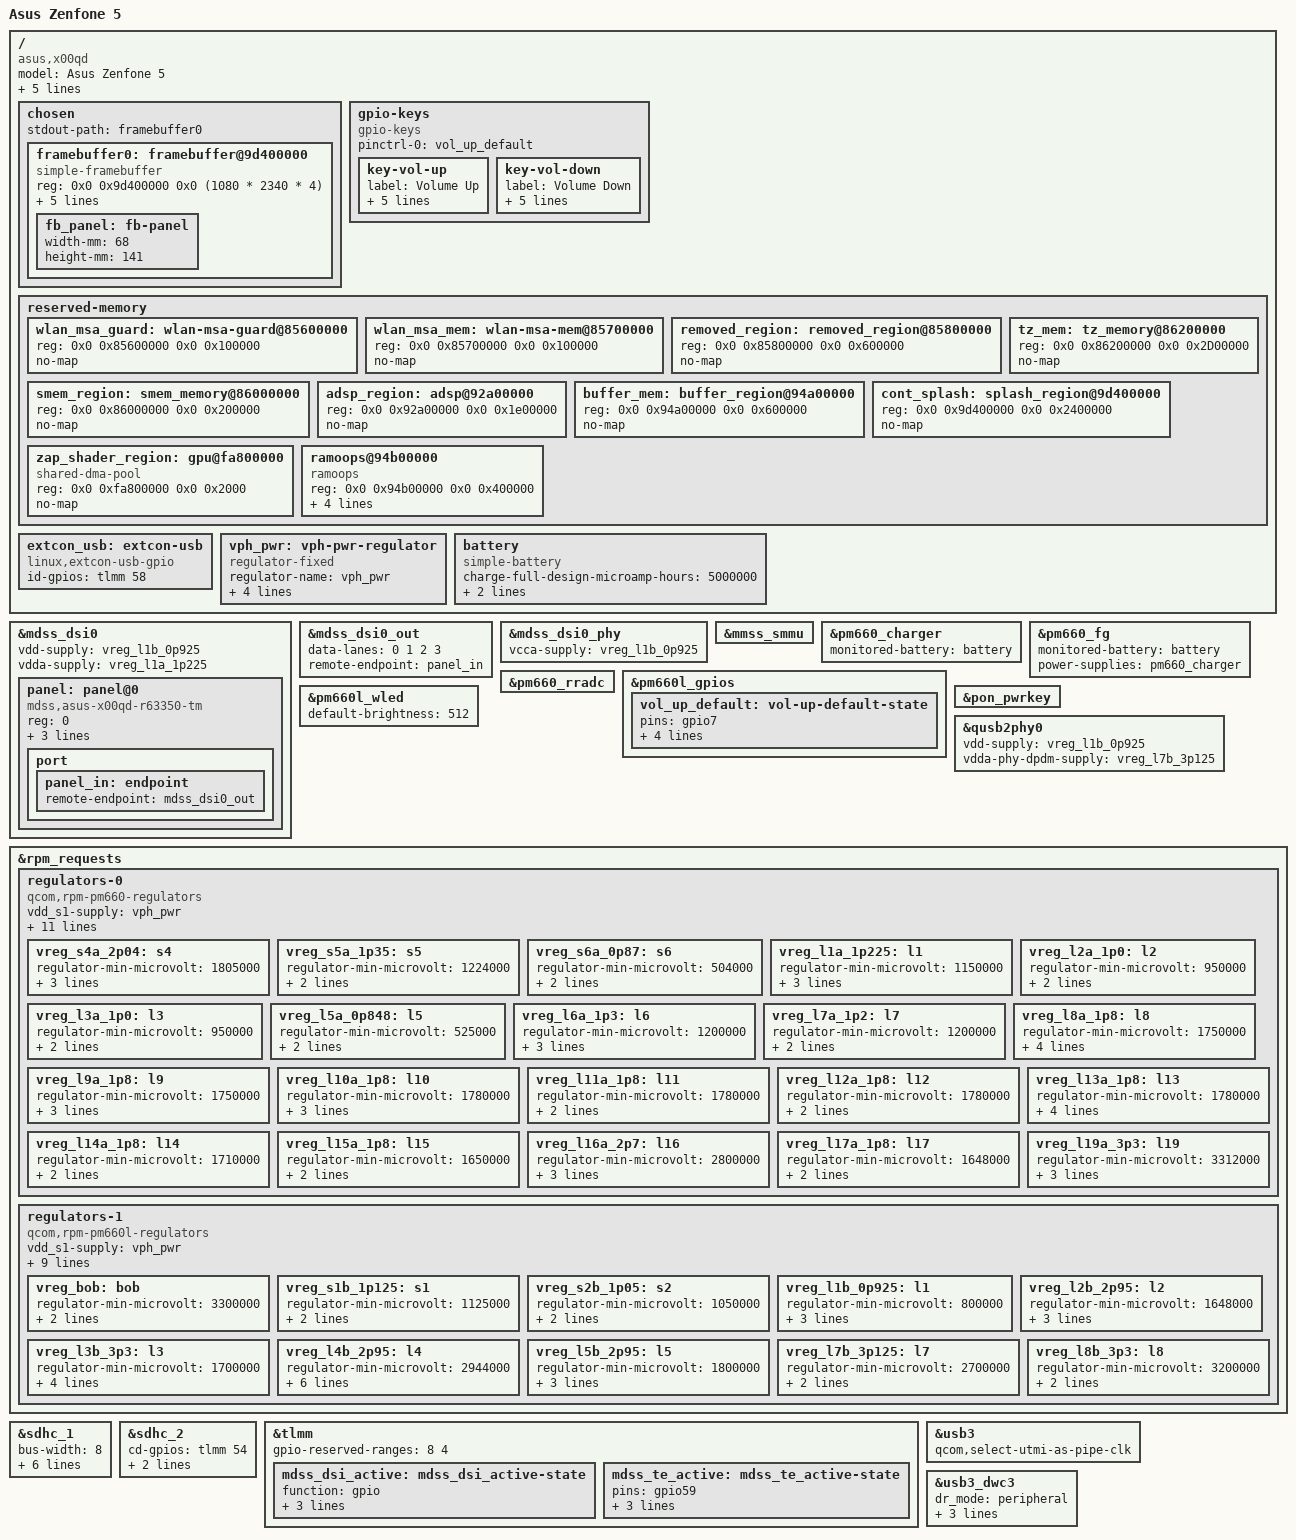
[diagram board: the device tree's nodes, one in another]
// SPDX-License-Identifier: GPL-2.0-only
/*
 * Copyright (c) 2025, Antony Kurniawan S. <postmarketos@smankusors.com>
 */

/dts-v1/;

#include "sdm636.dtsi"
#include "pm660.dtsi"
#include "pm660l.dtsi"
#include <dt-bindings/input/input.h>
#include <dt-bindings/input/gpio-keys.h>
#include <dt-bindings/pinctrl/qcom,pmic-gpio.h>

/delete-node/ &qhee_code;
/delete-node/ &smem_region;
/delete-node/ &tz_mem;
/delete-node/ &adsp_region;
/delete-node/ &buffer_mem;
/delete-node/ &zap_shader_region;

/ {
	model = "Asus Zenfone 5";
	compatible = "asus,x00qd", "qcom,sdm660";
	chassis-type = "handset";

	qcom,msm-id = <0x159 0x0>;
	qcom,board-id = <0x1000b 0>,<63 0>,<62 0>;
	qcom,pmic-id = <0x1001b 0x101011a 0x0 0x0 0x1001b 0x201011a 0x0 0x0 0x1001b 0x0102001a 0x0 0x0>;

	chosen {
		#address-cells = <2>;
		#size-cells = <2>;
		ranges;

		stdout-path = "framebuffer0";

		framebuffer0: framebuffer@9d400000 {
			compatible = "simple-framebuffer";
			reg = <0x0 0x9d400000 0x0 (1080 * 2340 * 4)>;
			status = "okay";
			width = <1080>;
			height = <2340>;
			stride = <(1080 * 4)>;
			format = "a8r8g8b8";

			/* In order to allow simpledrm framebuffer to know
			 * physical dimensions */
			panel = <&fb_panel>;

			fb_panel: fb-panel {
				width-mm = <68>;
				height-mm = <141>;
			};
		};
	};

	gpio-keys {
		status = "okay";
		compatible = "gpio-keys";

		pinctrl-0 = <&vol_up_default>;
		pinctrl-names = "default";

		key-vol-up {
			label = "Volume Up";
			gpios = <&tlmm 44 GPIO_ACTIVE_LOW>;
			linux,input-type = <1>;
			linux,code = <KEY_VOLUMEUP>;
			wakeup-source;
			debounce-interval = <15>;
		};

		key-vol-down {
			label = "Volume Down";
			gpios = <&tlmm 43 GPIO_ACTIVE_LOW>;
			linux,input-type = <1>;
			linux,code = <KEY_VOLUMEDOWN>;
			wakeup-source;
			debounce-interval = <15>;
		};
	};

	reserved-memory {
		#address-cells = <2>;
		#size-cells = <2>;
		ranges;
		wlan_msa_guard: wlan-msa-guard@85600000 {
			reg = <0x0 0x85600000 0x0 0x100000>;
			no-map;
		};

		wlan_msa_mem: wlan-msa-mem@85700000 {
			reg = <0x0 0x85700000 0x0 0x100000>;
			no-map;
		};

		/* removed_regions in downstream / qhee_code */
		removed_region: removed_region@85800000 {
			reg = <0x0 0x85800000 0x0 0x600000>;
			no-map;
		};

		smem_region: smem_memory@86000000 {
			reg = <0x0 0x86000000 0x0 0x200000>;
			no-map;
		};

		/* tz_mem */
		tz_mem: tz_memory@86200000 {
			reg = <0x0 0x86200000 0x0 0x2D00000>;
			/* 0x86200000 + 0x2D00000 = 0x88F00000 */
			no-map;
		};

		/* adsp_fw_region */
		adsp_region: adsp@92a00000 {
			reg = <0x0 0x92a00000 0x0 0x1e00000>;
			no-map;
		};

		/* cdsp_fw_region */
		buffer_mem: buffer_region@94a00000 {
			reg = <0x0 0x94a00000 0x0 0x600000>;
			no-map;
		};

		/* cont_splash_region / framebuffer */
		cont_splash: splash_region@9d400000 {
			reg = <0x0 0x9d400000 0x0 0x2400000>;
			no-map;
		};

		zap_shader_region: gpu@fa800000 {
			compatible = "shared-dma-pool";
			reg = <0x0 0xfa800000 0x0 0x2000>;
			no-map;
		};

		ramoops@94b00000 {
			compatible = "ramoops";
			reg = <0x0 0x94b00000 0x0 0x400000>;
			console-size = <0x200000>;
			record-size = <0x0>;
			ftrace-size = <0x0>;
			pmsg-size = <0x200000>;
		};
	};

	/*
	 * Until we hook up type-c detection, we
	 * have to stick with this. But it works.
	 */
	extcon_usb: extcon-usb {
		compatible = "linux,extcon-usb-gpio";
		id-gpios = <&tlmm 58 GPIO_ACTIVE_HIGH>;
	};

	vph_pwr: vph-pwr-regulator {
		compatible = "regulator-fixed";
		regulator-name = "vph_pwr";
		regulator-min-microvolt = <3700000>;
		regulator-max-microvolt = <3700000>;
		regulator-always-on;
		regulator-boot-on;
	};

	battery: battery {
			compatible = "simple-battery";

			charge-full-design-microamp-hours = <5000000>;
			voltage-min-design-microvolt = <3400000>;
			voltage-max-design-microvolt = <4350000>;
	};
};

&mdss_dsi0 {
	status = "okay";

	#address-cells = <1>;
	#size-cells = <0>;

	vdd-supply = <&vreg_l1b_0p925>;
	vdda-supply = <&vreg_l1a_1p225>;

	panel: panel@0 {
		reg = <0>;
		compatible = "mdss,asus-x00qd-r63350-tm";

		backlight = <&pm660l_wled>;

		reset-gpios = <&tlmm 53 GPIO_ACTIVE_LOW>;

		pinctrl-0 = <&mdss_dsi_active &mdss_te_active>;
		pinctrl-names = "default";

		port {
			panel_in: endpoint {
				remote-endpoint = <&mdss_dsi0_out>;
			};
		};
	};
};

&mdss_dsi0_out {
	data-lanes = <0 1 2 3>;
	remote-endpoint = <&panel_in>;
};

&mdss_dsi0_phy {
	vcca-supply = <&vreg_l1b_0p925>;

	status = "okay";
};

&mmss_smmu {
	status = "okay";
};

&pm660_charger {
	monitored-battery = <&battery>;

	status = "okay";
};

&pm660_fg {
	status = "okay";
	monitored-battery = <&battery>;
	power-supplies = <&pm660_charger>;
};

&pm660_rradc {
	status = "okay";
};

&pm660l_gpios {
	vol_up_default: vol-up-default-state {
		pins = "gpio7";
		function = PMIC_GPIO_FUNC_NORMAL;
		bias-pull-up;
		input-enable;
		qcom,drive-strength = <PMIC_GPIO_STRENGTH_NO>;
	};
};

&pm660l_wled {
	default-brightness = <512>;

	status = "okay";
};

&pon_pwrkey {
	status = "okay";
};

&qusb2phy0 {
	vdd-supply = <&vreg_l1b_0p925>;
	vdda-phy-dpdm-supply = <&vreg_l7b_3p125>;

	status = "okay";
};

&rpm_requests {
	regulators-0 {
		compatible = "qcom,rpm-pm660-regulators";

		vdd_s1-supply = <&vph_pwr>;
		vdd_s2-supply = <&vph_pwr>;
		vdd_s3-supply = <&vph_pwr>;
		vdd_s4-supply = <&vph_pwr>;
		vdd_s5-supply = <&vph_pwr>;
		vdd_s6-supply = <&vph_pwr>;

		vdd_l1_l6_l7-supply = <&vreg_s5a_1p35>;
		vdd_l2_l3-supply = <&vreg_s2b_1p05>;
		vdd_l5-supply = <&vreg_s2b_1p05>;
		vdd_l8_l9_l10_l11_l12_l13_l14-supply = <&vreg_s4a_2p04>;
		vdd_l15_l16_l17_l18_l19-supply = <&vreg_bob>;

		/*
		 * S1A (FTAPC0), S2A (FTAPC1), S3A (HFAPC1) are managed
		 * by the Core Power Reduction hardened (CPRh) and the
		 * Operating State Manager (OSM) HW automatically.
		 */

		vreg_s4a_2p04: s4 {
			regulator-min-microvolt = <1805000>;
			regulator-max-microvolt = <2040000>;
			regulator-enable-ramp-delay = <200>;
			regulator-always-on;
		};

		vreg_s5a_1p35: s5 {
			regulator-min-microvolt = <1224000>;
			regulator-max-microvolt = <1350000>;
			regulator-enable-ramp-delay = <200>;
		};

		vreg_s6a_0p87: s6 {
			regulator-min-microvolt = <504000>;
			regulator-max-microvolt = <992000>;
			regulator-enable-ramp-delay = <150>;
		};

		/* LDOs */
		vreg_l1a_1p225: l1 {
			regulator-min-microvolt = <1150000>;
			regulator-max-microvolt = <1250000>;
			regulator-enable-ramp-delay = <250>;
			regulator-allow-set-load;
		};

		vreg_l2a_1p0: l2 {
			regulator-min-microvolt = <950000>;
			regulator-max-microvolt = <1010000>;
			regulator-enable-ramp-delay = <250>;
		};

		vreg_l3a_1p0: l3 {
			regulator-min-microvolt = <950000>;
			regulator-max-microvolt = <1010000>;
			regulator-enable-ramp-delay = <250>;
		};

		vreg_l5a_0p848: l5 {
			regulator-min-microvolt = <525000>;
			regulator-max-microvolt = <950000>;
			regulator-enable-ramp-delay = <250>;
		};

		vreg_l6a_1p3: l6 {
			regulator-min-microvolt = <1200000>;
			regulator-max-microvolt = <1370000>;
			regulator-allow-set-load;
			regulator-enable-ramp-delay = <250>;
		};

		vreg_l7a_1p2: l7 {
			regulator-min-microvolt = <1200000>;
			regulator-max-microvolt = <1200000>;
			regulator-enable-ramp-delay = <250>;
		};

		vreg_l8a_1p8: l8 {
			regulator-min-microvolt = <1750000>;
			regulator-max-microvolt = <1800000>;
			regulator-enable-ramp-delay = <250>;
			regulator-system-load = <325000>;
			regulator-allow-set-load;
		};

		vreg_l9a_1p8: l9 {
			regulator-min-microvolt = <1750000>;
			regulator-max-microvolt = <1900000>;
			regulator-enable-ramp-delay = <250>;
			regulator-allow-set-load;
		};

		vreg_l10a_1p8: l10 {
			regulator-min-microvolt = <1780000>;
			regulator-max-microvolt = <1950000>;
			regulator-enable-ramp-delay = <250>;
			regulator-allow-set-load;
		};

		vreg_l11a_1p8: l11 {
			regulator-min-microvolt = <1780000>;
			regulator-max-microvolt = <1950000>;
			regulator-enable-ramp-delay = <250>;
		};

		vreg_l12a_1p8: l12 {
			regulator-min-microvolt = <1780000>;
			regulator-max-microvolt = <1950000>;
			regulator-enable-ramp-delay = <250>;
		};

		/* This gives power to the LPDDR4: never turn it off! */
		vreg_l13a_1p8: l13 {
			regulator-min-microvolt = <1780000>;
			regulator-max-microvolt = <1950000>;
			regulator-enable-ramp-delay = <250>;
			regulator-boot-on;
			regulator-always-on;
		};

		vreg_l14a_1p8: l14 {
			regulator-min-microvolt = <1710000>;
			regulator-max-microvolt = <1900000>;
			regulator-enable-ramp-delay = <250>;
		};

		vreg_l15a_1p8: l15 {
			regulator-min-microvolt = <1650000>;
			regulator-max-microvolt = <2950000>;
			regulator-enable-ramp-delay = <250>;
		};

		vreg_l16a_2p7: l16 {
			regulator-min-microvolt = <2800000>;
			regulator-max-microvolt = <2800000>;
			regulator-enable-ramp-delay = <250>;
			regulator-always-on;
		};

		vreg_l17a_1p8: l17 {
			regulator-min-microvolt = <1648000>;
			regulator-max-microvolt = <2952000>;
			regulator-enable-ramp-delay = <250>;
		};

		vreg_l19a_3p3: l19 {
			regulator-min-microvolt = <3312000>;
			regulator-max-microvolt = <3400000>;
			regulator-enable-ramp-delay = <250>;
			regulator-allow-set-load;
		};
	};

	regulators-1 {
		compatible = "qcom,rpm-pm660l-regulators";

		vdd_s1-supply = <&vph_pwr>;
		vdd_s2-supply = <&vph_pwr>;
		vdd_s3_s4-supply = <&vph_pwr>;
		vdd_s5-supply = <&vph_pwr>;
		vdd_s6-supply = <&vph_pwr>;

		vdd_l1_l9_l10-supply = <&vreg_s2b_1p05>;
		vdd_l2-supply = <&vreg_bob>;
		vdd_l3_l5_l7_l8-supply = <&vreg_bob>;
		vdd_l4_l6-supply = <&vreg_bob>;
		vdd_bob-supply = <&vph_pwr>;

		vreg_bob: bob {
			regulator-min-microvolt = <3300000>;
			regulator-max-microvolt = <3600000>;
			regulator-enable-ramp-delay = <500>;
		};

		vreg_s1b_1p125: s1 {
			regulator-min-microvolt = <1125000>;
			regulator-max-microvolt = <1125000>;
			regulator-enable-ramp-delay = <200>;
		};

		vreg_s2b_1p05: s2 {
			regulator-min-microvolt = <1050000>;
			regulator-max-microvolt = <1050000>;
			regulator-enable-ramp-delay = <200>;
		};

		/* LDOs */
		vreg_l1b_0p925: l1 {
			regulator-min-microvolt = <800000>;
			regulator-max-microvolt = <925000>;
			regulator-enable-ramp-delay = <250>;
			regulator-allow-set-load;
		};

		/* SDHCI 3.3V signal doesn't seem to be supported. */
		vreg_l2b_2p95: l2 {
			regulator-min-microvolt = <1648000>;
			regulator-max-microvolt = <3100000>;
			regulator-enable-ramp-delay = <250>;
			regulator-allow-set-load;
		};

		vreg_l3b_3p3: l3 {
			regulator-min-microvolt = <1700000>;
			regulator-max-microvolt = <3300000>;
			regulator-enable-ramp-delay = <250>;
			regulator-allow-set-load;
			regulator-always-on;
		};

		vreg_l4b_2p95: l4 {
			regulator-min-microvolt = <2944000>;
			regulator-max-microvolt = <2952000>;
			regulator-enable-ramp-delay = <250>;

			regulator-min-microamp = <200>;
			regulator-max-microamp = <600000>;
			regulator-system-load = <570000>;
			regulator-allow-set-load;
		};

		/*
		 * Downstream specifies a range of 1721-3600mV,
		 * but the only assigned consumers are SDHCI2 VMMC
		 * and Coresight QPDI that both request pinned 2.95V.
		 * Tighten the range to 1.8-3.328 (closest to 3.3) to
		 * make the mmc driver happy.
		 */
		vreg_l5b_2p95: l5 {
			regulator-min-microvolt = <1800000>;
			regulator-max-microvolt = <3328000>;
			regulator-enable-ramp-delay = <250>;
			regulator-allow-set-load;
		};

		vreg_l7b_3p125: l7 {
			regulator-min-microvolt = <2700000>;
			regulator-max-microvolt = <3125000>;
			regulator-enable-ramp-delay = <250>;
		};

		vreg_l8b_3p3: l8 {
			regulator-min-microvolt = <3200000>;
			regulator-max-microvolt = <3400000>;
			regulator-enable-ramp-delay = <250>;
		};
	};
};

&sdhc_1 {
	bus-width = <8>;
	non-removable;
	mmc-ddr-1_8v;
	mmc-hs200-1_8v;
	mmc-hs400-1_8v;
	vmmc-supply = <&vreg_l4b_2p95>;
	vqmmc-supply = <&vreg_l8a_1p8>;

	status = "okay";
};

&sdhc_2 {
	cd-gpios = <&tlmm 54 GPIO_ACTIVE_HIGH>;

	vmmc-supply = <&vreg_l5b_2p95>;
	vqmmc-supply = <&vreg_l2b_2p95>;

	status = "okay";
};

&tlmm {
	gpio-reserved-ranges = <8 4>;

	mdss_dsi_active: mdss_dsi_active-state {
		function = "gpio";
		pins = "gpio53";
		drive-strength = <8>;
		bias-disable;
	};

	mdss_te_active: mdss_te_active-state {
		pins = "gpio59";
		function = "mdp_vsync";
		drive-strength = <2>;
		bias-pull-down;
	};
};

&usb3 {
	qcom,select-utmi-as-pipe-clk;

	status = "okay";
};

&usb3_dwc3 {
	dr_mode = "peripheral";
	extcon = <&extcon_usb>;

	maximum-speed = "high-speed";
	phys = <&qusb2phy0>;
	phy-names = "usb2-phy";

	status = "okay";
};
